# AST1080 register map
File version: 1.0
CPU: CM4 r0p1, little endian, MPU, FPU, 4 interrupt priority bits, 256 interrupts
Registers are 32-bit, read-write, reset 0x0 unless marked. A register's access mark holds for its fields unless they carry their own. Offsets are from the block's base; [hi:lo] are bit positions; {n}, {i} and the like mark numbered series.

## spif
Base 0x74000400
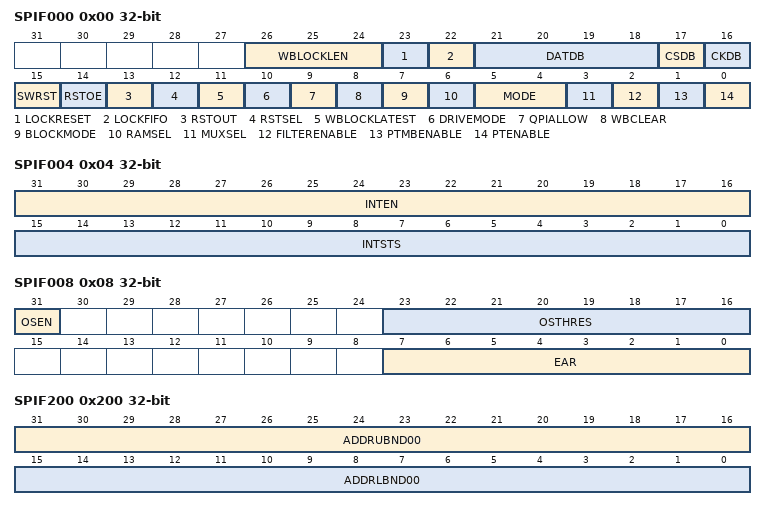
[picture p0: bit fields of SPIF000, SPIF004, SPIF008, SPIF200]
0x00 SPIF000 — SPIF\_CFG
  [26:24] WBLOCKLEN ro, [23] LOCKRESET, [22] LOCKFIFO, [21:18] DATDB, [17] CSDB, [16] CKDB, [15] SWRST, [14] RSTOE, [13] RSTOUT, [12] RSTSEL, [11] WBLOCKLATEST, [10] DRIVEMODE, [9] QPIALLOW, [8] WBCLEAR, [7] BLOCKMODE, [6] RAMSEL, [5:4] MODE, [3] MUXSEL, [2] FILTERENABLE, [1] PTMBENABLE, [0] PTENABLE
0x04 SPIF004 — SPIF\_IRQ
  [31:16] INTEN, [15:0] INTSTS
0x08 SPIF008 — SPIF\_OS
  [31] OSEN, [23:16] OSTHRES, [7:0] EAR ro
0x0C SPIF00C — SPIF\_ELOG\_CNT
  [7:0] ELOGCNT
0x10 SPIF010 — SPIF\_CSBASE0
  [15:0] CS0BASE
0x14 SPIF014 — SPIF\_CSBASE1
  [15:0] CS1BASE
0x18 SPIF018 — SPIF\_CSBASE2
  [15:0] CS2BASE
0x1C SPIF01C — SPIF\_CSBASE3
  [15:0] CS3BASE
0x20 SPIF020 — SPIF\_WLOCKTB
  [31:0] WTABLEWLOCK
0x40 SPIF040 — SPIF\_ELOG00
  [31:0] ELOG00
0x44 SPIF044 — SPIF\_ELOG01
  [31:0] ELOG01
0x48 SPIF048 — SPIF\_ELOG02
  [31:0] ELOG02
0x4C SPIF04C — SPIF\_ELOG03
  [31:0] ELOG03
0x50 SPIF050 — SPIF\_ELOG04
  [31:0] ELOG04
0x54 SPIF054 — SPIF\_ELOG05
  [31:0] ELOG05
0x58 SPIF058 — SPIF\_ELOG06
  [31:0] ELOG06
0x5C SPIF05C — SPIF\_ELOG07
  [31:0] ELOG07
0x7C SPIF07C — SPIF\_WLOCK
  [31:0] WLOCK
0x80 SPIF080 — SPIF\_WTABLE00
  [31:0] WTABLE00
0x84 SPIF084 — SPIF\_WTABLE01
  [31:0] WTABLE01
0x88 SPIF088 — SPIF\_WTABLE02
  [31:0] WTABLE02
0x8C SPIF08C — SPIF\_WTABLE03
  [31:0] WTABLE03
0x90 SPIF090 — SPIF\_WTABLE04
  [31:0] WTABLE04
0x94 SPIF094 — SPIF\_WTABLE05
  [31:0] WTABLE05
0x98 SPIF098 — SPIF\_WTABLE06
  [31:0] WTABLE06
0x9C SPIF09C — SPIF\_WTABLE07
  [31:0] WTABLE07
0xA0 SPIF0A0 — SPIF\_WTABLE08
  [31:0] WTABLE08
0xA4 SPIF0A4 — SPIF\_WTABLE09
  [31:0] WTABLE09
0xA8 SPIF0A8 — SPIF\_WTABLE10
  [31:0] WTABLE10
0xAC SPIF0AC — SPIF\_WTABLE11
  [31:0] WTABLE11
0xB0 SPIF0B0 — SPIF\_WTABLE12
  [31:0] WTABLE12
0xB4 SPIF0B4 — SPIF\_WTABLE13
  [31:0] WTABLE13
0xB8 SPIF0B8 — SPIF\_WTABLE14
  [31:0] WTABLE14
0xBC SPIF0BC — SPIF\_WTABLE15
  [31:0] WTABLE15
0xC0 SPIF0C0 — SPIF\_WTABLE16
  [31:0] WTABLE16
0xC4 SPIF0C4 — SPIF\_WTABLE17
  [31:0] WTABLE17
0xC8 SPIF0C8 — SPIF\_WTABLE18
  [31:0] WTABLE18
0xCC SPIF0CC — SPIF\_WTABLE19
  [31:0] WTABLE19
0xD0 SPIF0D0 — SPIF\_WTABLE20
  [31:0] WTABLE20
0xD4 SPIF0D4 — SPIF\_WTABLE21
  [31:0] WTABLE21
0xD8 SPIF0D8 — SPIF\_WTABLE22
  [31:0] WTABLE22
0xDC SPIF0DC — SPIF\_WTABLE23
  [31:0] WTABLE23
0xE0 SPIF0E0 — SPIF\_WTABLE24
  [31:0] WTABLE24
0xE4 SPIF0E4 — SPIF\_WTABLE25
  [31:0] WTABLE25
0xE8 SPIF0E8 — SPIF\_WTABLE26
  [31:0] WTABLE26
0xEC SPIF0EC — SPIF\_WTABLE27
  [31:0] WTABLE27
0xF0 SPIF0F0 — SPIF\_WTABLE28
  [31:0] WTABLE28
0xF4 SPIF0F4 — SPIF\_WTABLE29
  [31:0] WTABLE29
0xF8 SPIF0F8 — SPIF\_WTABLE30
  [31:0] WTABLE30
0xFC SPIF0FC — SPIF\_WTABLE31
  [31:0] WTABLE31
0x100 SPIF100 — SPIF\_ADDRCTL00
  [3:0] ADDRCTL00
0x104 SPIF104 — SPIF\_ADDRCTL01
  [3:0] ADDRCTL01
0x108 SPIF108 — SPIF\_ADDRCTL02
  [3:0] ADDRCTL02
{0x6C+0x10*i} SPIF{i}C (i=10..13) — SPIF\_ADDRCTL{4i-37:02}
  [3:0] ADDRCTL{4i-37:02}
0x110 SPIF110 — SPIF\_ADDRCTL04
  [3:0] ADDRCTL04
0x114 SPIF114 — SPIF\_ADDRCTL05
  [3:0] ADDRCTL05
0x118 SPIF118 — SPIF\_ADDRCTL06
  [3:0] ADDRCTL06
0x120 SPIF120 — SPIF\_ADDRCTL08
  [3:0] ADDRCTL08
0x124 SPIF124 — SPIF\_ADDRCTL09
  [3:0] ADDRCTL09
0x128 SPIF128 — SPIF\_ADDRCTL10
  [3:0] ADDRCTL10
0x130 SPIF130 — SPIF\_ADDRCTL12
  [3:0] ADDRCTL12
0x134 SPIF134 — SPIF\_ADDRCTL13
  [3:0] ADDRCTL13
0x138 SPIF138 — SPIF\_ADDRCTL14
  [3:0] ADDRCTL14
0x200 SPIF200 — SPIF\_ADDRBND00
  [31:16] ADDRUBND00, [15:0] ADDRLBND00
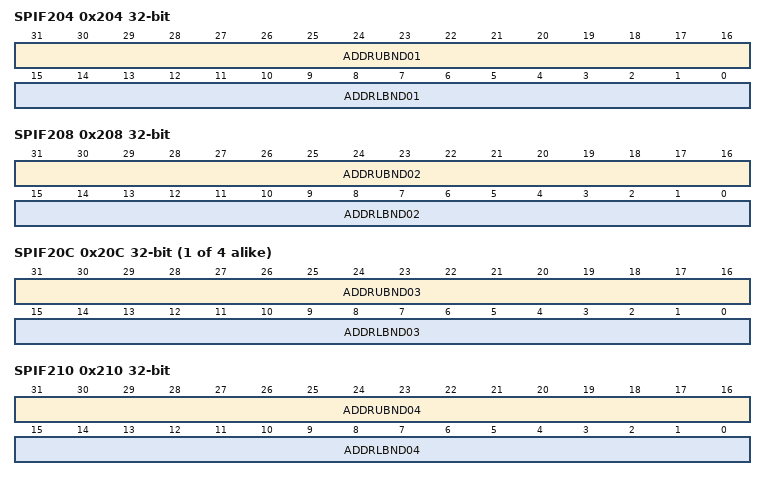
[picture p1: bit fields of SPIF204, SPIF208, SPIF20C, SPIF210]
0x204 SPIF204 — SPIF\_ADDRBND01
  [31:16] ADDRUBND01, [15:0] ADDRLBND01
0x208 SPIF208 — SPIF\_ADDRBND02
  [31:16] ADDRUBND02, [15:0] ADDRLBND02
{0xCC+0x10*i} SPIF{i}C (i=20..23) — SPIF\_ADDRBND{4i-77:02}
  [31:16] ADDRUBND{4i-77:02}, [15:0] ADDRLBND{4i-77:02}
0x210 SPIF210 — SPIF\_ADDRBND04
  [31:16] ADDRUBND04, [15:0] ADDRLBND04
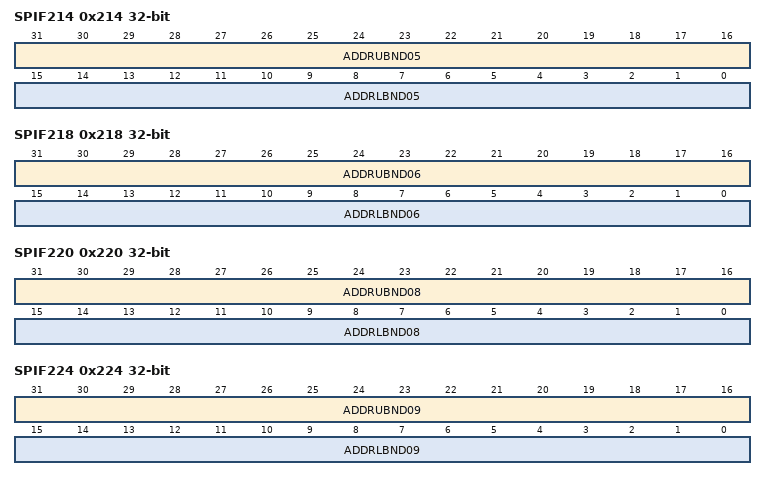
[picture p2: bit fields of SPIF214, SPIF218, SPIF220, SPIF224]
0x214 SPIF214 — SPIF\_ADDRBND05
  [31:16] ADDRUBND05, [15:0] ADDRLBND05
0x218 SPIF218 — SPIF\_ADDRBND06
  [31:16] ADDRUBND06, [15:0] ADDRLBND06
0x220 SPIF220 — SPIF\_ADDRBND08
  [31:16] ADDRUBND08, [15:0] ADDRLBND08
0x224 SPIF224 — SPIF\_ADDRBND09
  [31:16] ADDRUBND09, [15:0] ADDRLBND09
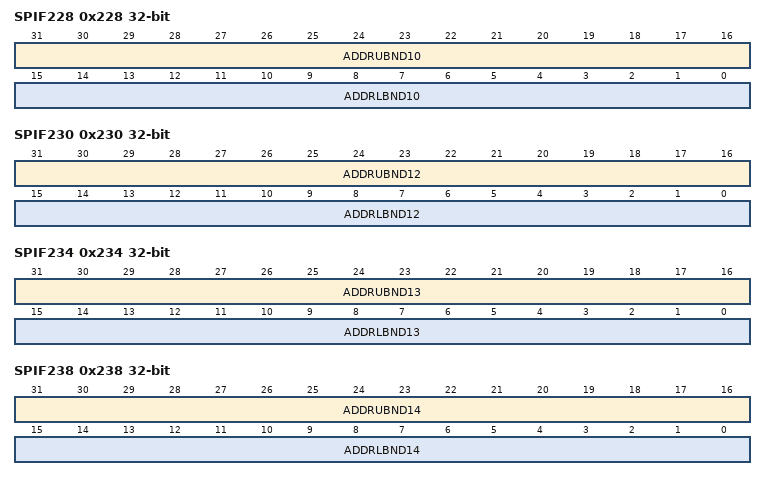
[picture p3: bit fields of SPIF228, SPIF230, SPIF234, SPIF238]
0x228 SPIF228 — SPIF\_ADDRBND10
  [31:16] ADDRUBND10, [15:0] ADDRLBND10
0x230 SPIF230 — SPIF\_ADDRBND12
  [31:16] ADDRUBND12, [15:0] ADDRLBND12
0x234 SPIF234 — SPIF\_ADDRBND13
  [31:16] ADDRUBND13, [15:0] ADDRLBND13
0x238 SPIF238 — SPIF\_ADDRBND14
  [31:16] ADDRUBND14, [15:0] ADDRLBND14
0x300 SPIF300 — SPIF\_WPWTABLE\_EN
  [31:0] WPWTABLEEN
0x310 SPIF310 — SPIF\_WPADDRCTL
  [31:0] WPADDRCTL
